AUTOSAR XML (schema 4-3-0)
package /ComponentTypes
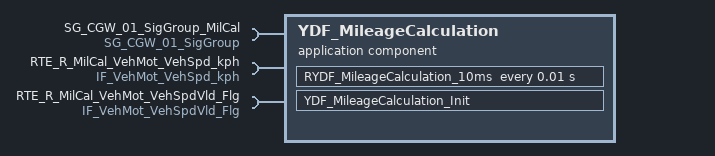
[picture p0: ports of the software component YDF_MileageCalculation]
  application sw component type YDF_MileageCalculation
    require port SG_CGW_01_SigGroup_MilCal: nonqueued-receiver-com-spec{data-element=SG_CGW_01_SigGroup, uses-end-to-end-protection=true, enable-update=true, filter=data-filter-type=ALWAYS, init-value=fields=[CGW_VehicleState:0, Checksum_278:0, MessageCounter_278:0]}, required-interface=SG_CGW_01_SigGroup
    require port RTE_R_MilCal_VehMot_VehSpd_kph: nonqueued-receiver-com-spec{data-element=tec_VehMot_VehSpd_kph, filter=data-filter-type=ALWAYS}, required-interface=IF_VehMot_VehSpd_kph
    require port RTE_R_MilCal_VehMot_VehSpdVld_Flg: nonqueued-receiver-com-spec{data-element=tec_VehMot_VehSpdVld_Flg, filter=data-filter-type=ALWAYS}, required-interface=IF_VehMot_VehSpdVld_Flg
    behavior YDF_MileageCalculation_InternalBehavior
      init event YDF_MileageCalculation_InitEvent: start-on-event=YDF_MileageCalculation_Init
      timing event TMT_RYDF_MileageCalculation_10ms: start-on-event=RYDF_MileageCalculation_10ms, period=0.01
      runnable RYDF_MileageCalculation_10ms
        data-receive-point-by-arguments:
          access REC_SG_CGW_01_SigGroup_SG_CGW_01_SigGroup: accessed-variable=SG_CGW_01_SigGroup_MilCal.SG_CGW_01_SigGroup
          access REC_RTE_R_MilCal_VehMot_VehSpdVld_Flg_tec_VehMot_VehSpdVld_Flg: accessed-variable=RTE_R_MilCal_VehMot_VehSpdVld_Flg.tec_VehMot_VehSpdVld_Flg
          access REC_RTE_R_MilCal_VehMot_VehSpd_kph_tec_VehMot_VehSpd_kph: accessed-variable=RTE_R_MilCal_VehMot_VehSpd_kph.tec_VehMot_VehSpd_kph
      runnable YDF_MileageCalculation_Init
  swc implementation YDF_MileageCalculation_Implementation: behavior=YDF_MileageCalculation_InternalBehavior
